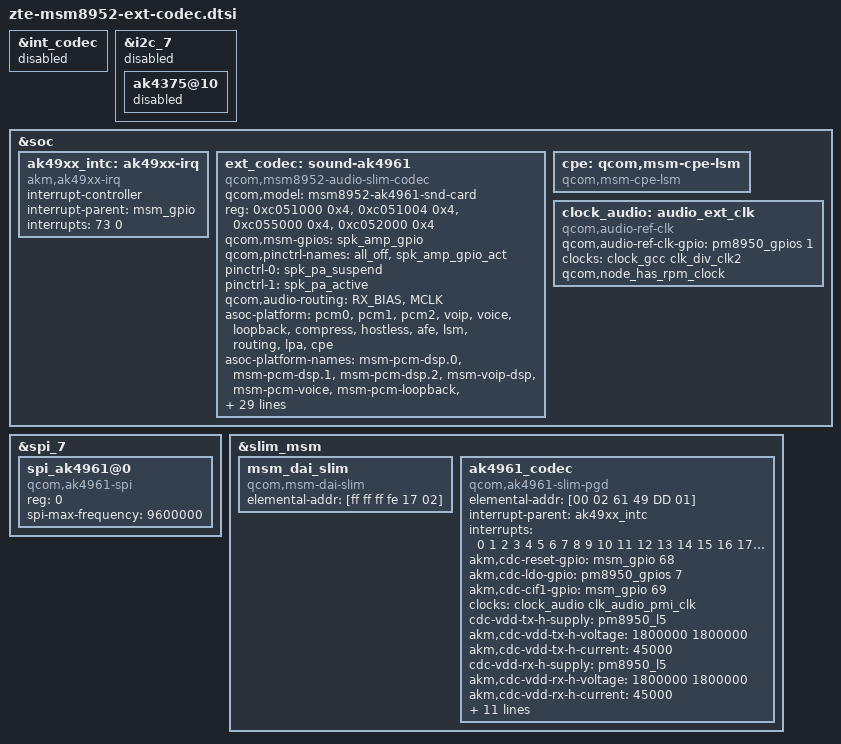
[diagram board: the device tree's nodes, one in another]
/*
 * Copyright (c) 2015, The Linux Foundation. All rights reserved.
 *
 * This program is free software; you can redistribute it and/or modify
 * it under the terms of the GNU General Public License version 2 and
 * only version 2 as published by the Free Software Foundation.
 *
 * This program is distributed in the hope that it will be useful,
 * but WITHOUT ANY WARRANTY; without even the implied warranty of
 * MERCHANTABILITY or FITNESS FOR A PARTICULAR PURPOSE.  See the
 * GNU General Public License for more details.
 */

&int_codec {
	status = "disabled";
};

&i2c_7 { /* BLSP2 QUP3 */
		status = "disabled";
		ak4375@10 {
			status = "disabled";
		  };
};

&soc {
	ak49xx_intc: ak49xx-irq {
		compatible = "akm,ak49xx-irq";
		interrupt-controller;
		#interrupt-cells = <1>;
		interrupt-parent = <&msm_gpio>;
		interrupts = <73 0>;
		interrupt-names = "cdc-int";
	};

	ext_codec: sound-ak4961 {
		compatible = "qcom,msm8952-audio-slim-codec";
		qcom,model = "msm8952-ak4961-snd-card";

		reg = <0xc051000 0x4>,
		    <0xc051004 0x4>,
		    <0xc055000 0x4>,
		    <0xc052000 0x4>;
		reg-names = "csr_gp_io_mux_mic_ctl",
			"csr_gp_io_mux_spkr_ctl",
			"csr_gp_io_lpaif_pri_pcm_pri_mode_muxsel",
			"csr_gp_io_mux_quin_ctl";
		qcom,msm-gpios =
			"spk_amp_gpio";
		qcom,pinctrl-names =
			"all_off",
			"spk_amp_gpio_act";
		pinctrl-names =
			"all_off",
			"spk_amp_gpio_act";
		pinctrl-0 = <&spk_pa_suspend>;
		pinctrl-1 = <&spk_pa_active>;

		qcom,audio-routing =
			"RX_BIAS", "MCLK";

		asoc-platform = <&pcm0>, <&pcm1>, <&pcm2>, <&voip>, <&voice>,
				<&loopback>, <&compress>, <&hostless>,
				<&afe>, <&lsm>, <&routing>, <&lpa>, <&cpe>;
		asoc-platform-names = "msm-pcm-dsp.0", "msm-pcm-dsp.1", "msm-pcm-dsp.2",
				"msm-voip-dsp", "msm-pcm-voice", "msm-pcm-loopback",
				"msm-compress-dsp", "msm-pcm-hostless", "msm-pcm-afe",
				"msm-lsm-client", "msm-pcm-routing", "msm-pcm-lpa",
				"msm-cpe-lsm";
		asoc-cpu = <&dai_pri_auxpcm>, <&dai_hdmi>, <&dai_mi2s0>, <&dai_mi2s1>,<&dai_mi2s2>,
				<&dai_mi2s3>, <&dai_mi2s5>, <&sb_0_rx>, <&sb_0_tx>,
				<&sb_1_rx>, <&sb_1_tx>, <&sb_3_rx>, <&sb_3_tx>,
				<&sb_4_rx>, <&sb_4_tx>, <&sb_5_tx>, <&bt_sco_rx>,
				<&bt_sco_tx>, <&int_fm_rx>, <&int_fm_tx>, <&afe_pcm_rx>,
				<&afe_pcm_tx>, <&afe_proxy_rx>, <&afe_proxy_tx>,
				<&incall_record_rx>, <&incall_record_tx>, <&incall_music_rx>,
				<&incall_music_2_rx>;
		asoc-cpu-names = "msm-dai-q6-auxpcm.1",	"msm-dai-q6-hdmi.8", "msm-dai-q6-mi2s.0",
				"msm-dai-q6-mi2s.1", "msm-dai-q6-mi2s.2",
				"msm-dai-q6-mi2s.3",
				"msm-dai-q6-mi2s.5", "msm-dai-q6-dev.16384",
				"msm-dai-q6-dev.16385", "msm-dai-q6-dev.16386",
				"msm-dai-q6-dev.16387", "msm-dai-q6-dev.16390",
				"msm-dai-q6-dev.16391", "msm-dai-q6-dev.16392",
				"msm-dai-q6-dev.16393", "msm-dai-q6-dev.16395",
				"msm-dai-q6-dev.12288", "msm-dai-q6-dev.12289",
				"msm-dai-q6-dev.12292", "msm-dai-q6-dev.12293",
				"msm-dai-q6-dev.224", "msm-dai-q6-dev.225",
				"msm-dai-q6-dev.241", "msm-dai-q6-dev.240",
				"msm-dai-q6-dev.32771", "msm-dai-q6-dev.32772",
				"msm-dai-q6-dev.32773", "msm-dai-q6-dev.32770";
		asoc-codec = <&stub_codec>;
		asoc-codec-names = "msm-stub-codec.1";
	};

	cpe: qcom,msm-cpe-lsm {
		compatible = "qcom,msm-cpe-lsm";
	};

	clock_audio: audio_ext_clk {
		compatible = "qcom,audio-ref-clk";
		qcom,audio-ref-clk-gpio = <&pm8950_gpios 1 0>;
		clock-names = "osr_clk";
		clocks = <&clock_gcc clk_div_clk2>;
		qcom,node_has_rpm_clock;
		#clock-cells = <1>;
	};
};

&spi_7 { /* BLSP2 QUP2 */
	status = "ok";

	spi_ak4961@0 {			
				compatible = "qcom,ak4961-spi";
				reg = <0>;
				spi-max-frequency = <9600000>;
			//	spi-cpol = <1>;
			//	spi-cpha= <1>;
	};
};

&slim_msm {
	status = "ok";
	msm_dai_slim {
		compatible = "qcom,msm-dai-slim";
		elemental-addr = [ff ff ff fe 17 02];
	};

	ak4961_codec {
		compatible = "qcom,ak4961-slim-pgd";
		elemental-addr = [00 02 61 49 DD 01];

		interrupt-parent = <&ak49xx_intc>;
		interrupts = <0 1 2 3 4 5 6 7 8 9 10 11 12 13 14 15 16
			17 18 19 20 21 22 23 24 25 26 27 28 29
			30 31>;

		akm,cdc-reset-gpio = <&msm_gpio 68 0>;
                    akm,cdc-ldo-gpio = <&pm8950_gpios 7 0>;
		      akm,cdc-cif1-gpio=<&msm_gpio 69 0>;
		//	  akm,cdc-cs-gpio=<&msm_gpio 2 0>;

		clock-names = "cdc_clk";
		clocks = <&clock_audio clk_audio_pmi_clk>;

		// cdc-vdd-buck-supply = <&eldo2_8952>;
		// qcom,cdc-vdd-buck-voltage = <2150000 2150000>;
		// qcom,cdc-vdd-buck-current = <650000>;

		cdc-vdd-tx-h-supply = <&pm8950_l5>;
		akm,cdc-vdd-tx-h-voltage = <1800000 1800000>;
		akm,cdc-vdd-tx-h-current = <45000>;

		cdc-vdd-rx-h-supply = <&pm8950_l5>;
		akm,cdc-vdd-rx-h-voltage = <1800000 1800000>;
		akm,cdc-vdd-rx-h-current = <45000>;

		cdc-vdd-px-supply = <&pm8950_l5>;
		akm,cdc-vdd-px-voltage = <1800000 1800000>;
		akm,cdc-vdd-px-current = <45000>;

			akm,cdc-static-supplies = "cdc-vdd-tx-h",
						   "cdc-vdd-rx-h",
						   "cdc-vdd-px";

			akm,cdc-micbias-mpwr1-mv = <0>;
			akm,cdc-micbias-mpwr2-mv = <2800>;

			akm,cdc-mclk-clk-rate = <9600000>;
			akm,cdc-slim-ifd = "ak4961-slim-ifd";
			akm,cdc-slim-ifd-elemental-addr = [00 00 61 49 DD 01];
	};
};
